# STM32MP21_CM33 register map
File version: 0.4
CPU: CM33 r0p1, little endian, MPU, FPU, vendor SysTick, 8 interrupt priority bits
Registers are 32-bit, read-write, reset 0x0 unless marked. A register's access mark holds for its fields unless they carry their own. Offsets are from the block's base; [hi:lo] are bit positions; {n}, {i} and the like mark numbered series.

## DDRDBG — DDRDBG address block description
Base 0x48050000
Same registers: DDRDBG_S 0x58050000
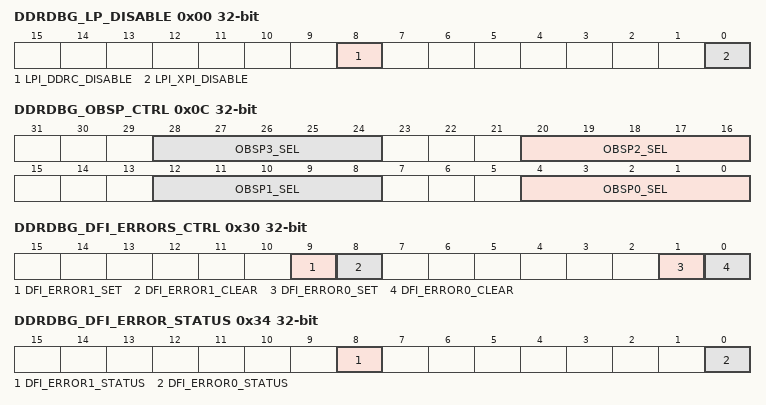
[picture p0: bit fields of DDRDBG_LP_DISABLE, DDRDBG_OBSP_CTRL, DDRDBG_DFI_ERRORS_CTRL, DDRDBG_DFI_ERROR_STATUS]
0x00 DDRDBG_LP_DISABLE — DDRDBG low-power disable register
  [8] LPI_DDRC_DISABLE
    0=No effect; 1=Disable automatic clock gating of DDRC when idle
  [0] LPI_XPI_DISABLE
    0=No effect; 1=Disable automatic clock gating of XPIs when idle
0x04 DDRDBG_BYPASS_PCLKEN
  [0] ENABLE
    0=No effect; 1=The DDRPHYC Bypass_Pclken is active
0x08 DDRDBG_DDRC_AUTO_SR_DELAY reset 0x20
  [7:0] DELAY_CYCLES — Number of delay cycles to wait before to gate down the DDRC clock when in auto self-refresh
0x0C DDRDBG_OBSP_CTRL — DDRDBG OBSP control register
  [8n+4:8n] OBSP{n}_SEL (n=0..3) — Selects which of the input observable signal is forwarded to the HDP on selectable observability line {n}.
0x10 DDRDBG_FRAC_PLL_LOCK
  [0] LOCK
    0=No effect; 1=PLL lock, direct copy of ddrss_pll2_lock
0x14 DDRDBG_DTO_OUTPUT
  [0] DTO — the DDRPHYC PLL lock can be observed in this register.
    0=No effect; 1=DDRPHYC DTO output is stored in this register
0x30 DDRDBG_DFI_ERRORS_CTRL — DDRDBG DFI error control register
  [9] DFI_ERROR1_SET
    0=No effect; 1=Trigger the interrupt linked with dfi_error
  [8] DFI_ERROR1_CLEAR
    0=No effect; 1=Clear the interrupt linked with dfi_error1
  [1] DFI_ERROR0_SET
    0=No effect; 1=Trigger the interrupt linked with dfi_error0
  [0] DFI_ERROR0_CLEAR
    0=No effect; 1=Clear the interrupt linked with dfi_error0
0x34 DDRDBG_DFI_ERROR_STATUS
  [8] DFI_ERROR1_STATUS — Status bit for dfi_error1
    0=No effect; 1=Clear the interrupt linked with dfi_error1
  [0] DFI_ERROR0_STATUS — Status bit for dfi_error0
    0=No effect; 1=Clear the interrupt linked with dfi_error0
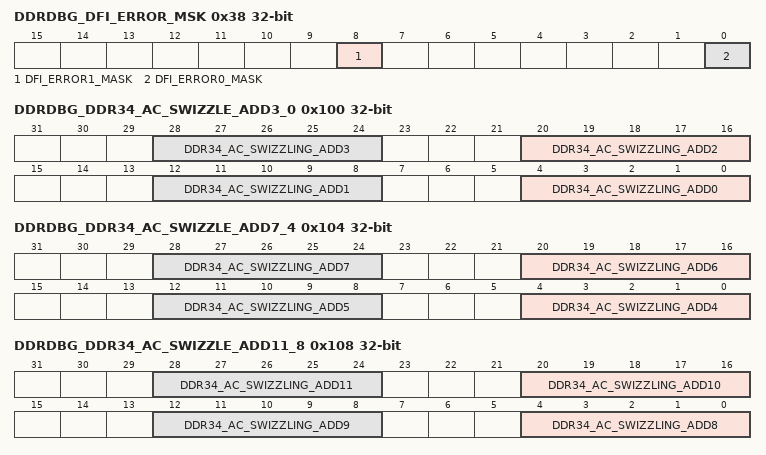
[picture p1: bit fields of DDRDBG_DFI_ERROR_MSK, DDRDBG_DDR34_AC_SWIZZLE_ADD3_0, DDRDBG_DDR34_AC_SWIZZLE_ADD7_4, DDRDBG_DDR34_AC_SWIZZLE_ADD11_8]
0x38 DDRDBG_DFI_ERROR_MSK — DDRDBG DFI error mask register
  [8] DFI_ERROR1_MASK
    0=No effect; 1=Interrupt linked to dfi_error1 is masked
  [0] DFI_ERROR0_MASK
    0=No effect; 1=Interrupt linked to dfi_error0 is masked
0x100 DDRDBG_DDR34_AC_SWIZZLE_ADD3_0
  [8n+4:8n] DDR34_AC_SWIZZLING_ADD{n} (n=0..3) — Remapping input bit on add{n} DDRPHYC input
0x104 DDRDBG_DDR34_AC_SWIZZLE_ADD7_4
  [8n-28:8n-32] DDR34_AC_SWIZZLING_ADD{n} (n=4..7) — Remapping input bit on add{n} DDRPHYC input
0x108 DDRDBG_DDR34_AC_SWIZZLE_ADD11_8
  [8n-60:8n-64] DDR34_AC_SWIZZLING_ADD{n} (n=8..11) — Remapping input bit on add{n} DDRPHYC input
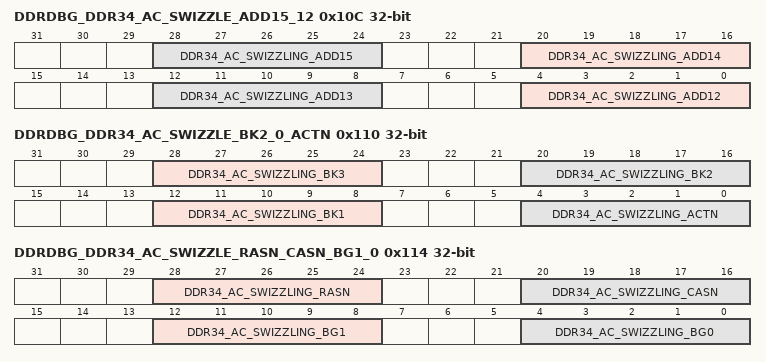
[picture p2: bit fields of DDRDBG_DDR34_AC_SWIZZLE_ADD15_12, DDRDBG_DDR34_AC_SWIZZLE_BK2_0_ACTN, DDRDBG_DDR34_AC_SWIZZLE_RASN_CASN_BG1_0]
0x10C DDRDBG_DDR34_AC_SWIZZLE_ADD15_12
  [8n-92:8n-96] DDR34_AC_SWIZZLING_ADD{n} (n=12..15) — Remapping input bit on add{n} DDRPHYC input
0x110 DDRDBG_DDR34_AC_SWIZZLE_BK2_0_ACTN
  [28:24] DDR34_AC_SWIZZLING_BK3 — Remapping input bit on bk3 DDRPHYC input
  [20:16] DDR34_AC_SWIZZLING_BK2 — Remapping input bit on bk2 DDRPHYC input
  [12:8] DDR34_AC_SWIZZLING_BK1 — Remapping input bit on bk1 DDRPHYC input
  [4:0] DDR34_AC_SWIZZLING_ACTN — Remapping input bit on actn DDRPHYC input
0x114 DDRDBG_DDR34_AC_SWIZZLE_RASN_CASN_BG1_0
  [28:24] DDR34_AC_SWIZZLING_RASN — Remapping input bit on rasn DDRPHYC input
  [20:16] DDR34_AC_SWIZZLING_CASN — Remapping input bit on casn DDRPHYC input
  [12:8] DDR34_AC_SWIZZLING_BG1 — Remapping input bit on bg1 DDRPHYC input
  [4:0] DDR34_AC_SWIZZLING_BG0 — Remapping input bit on bg0 DDRPHYC input
0x118 DDRDBG_DDR34_AC_SWIZZLE_WEN
  [4:0] DDR34_AC_SWIZZLING_WEN — Remapping input bit on wen DDRPHYC input

## HDP — HDP address block description
Base 0x44090000
Same registers: HDP_S 0x54090000
0x00 HDP_CTRL — HDP control register
  [0] EN — HDP enable (valid if enabled in BSEC)
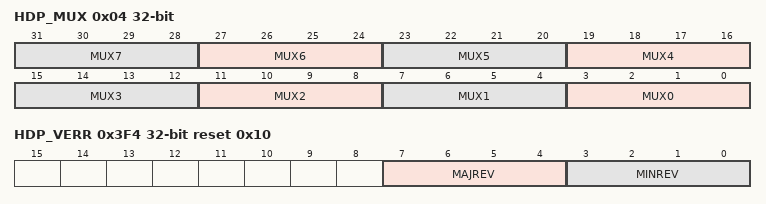
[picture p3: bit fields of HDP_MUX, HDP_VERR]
0x04 HDP_MUX — HDP multiplexer control register
  [4n+3:4n] MUX{n} (n=0..7) — Selection of the HDPy output among the 16 available signals
0x10 HDP_VAL ro — HDP read back value register
  [7:0] HDPVAL — Value of the HDP signals
0x14 HDP_GPOSET wo — HDP general purpose output set register
  [7:0] HDPGPOSET — When a bit is written to 1, the corresponding HDP GPO is set.
0x18 HDP_GPOCLR wo — HDP general purpose output clear register
  [7:0] HDPGPOCLR — When a bit is written to 1, the corresponding HDP GPO is cleared.
0x1C HDP_GPOVAL — HDP general purpose output value register
  [7:0] HDPGPOVAL — When written, this bit field defines the value of the HDP GPO.
0x3F4 HDP_VERR ro reset 0x10 — HDP version register
  [7:4] MAJREV — HDP major revision
  [3:0] MINREV — HDP minor revision
0x3F8 HDP_IPIDR ro reset 0x30002 — HDP identification register
  [31:0] ID — HDP identifier
0x3FC HDP_SIDR ro reset 0xA3C5DD01 — HDP size identification register
  [31:0] SID — Size identifier
